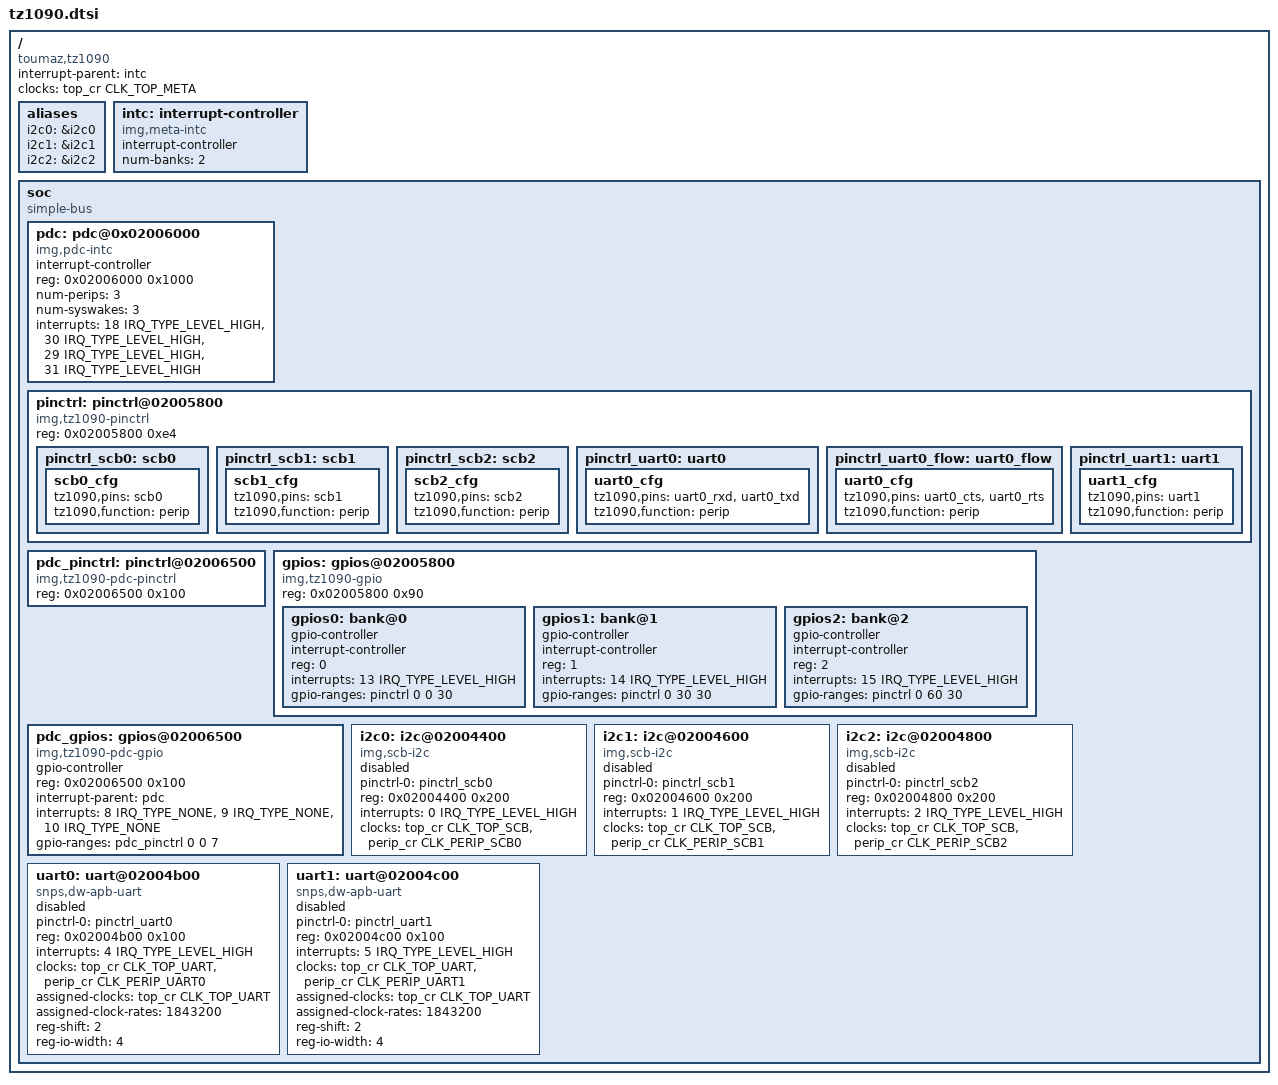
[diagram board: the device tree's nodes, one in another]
/*
 * Copyright (C) 2012 Imagination Technologies Ltd.
 *
 * This program is free software; you can redistribute it and/or modify
 * it under the terms of the GNU General Public License version 2 as
 * published by the Free Software Foundation.
 */

#include "skeleton.dtsi"

#include <dt-bindings/interrupt-controller/irq.h>
#include "tz1090_clk.dtsi"

/ {
	compatible = "toumaz,tz1090", "img,meta";

	interrupt-parent = <&intc>;

	clocks = <&top_cr CLK_TOP_META>;
	clock-names = "core";

	aliases {
		i2c0 = &i2c0;
		i2c1 = &i2c1;
		i2c2 = &i2c2;
	};

	intc: interrupt-controller {
		compatible = "img,meta-intc";
		interrupt-controller;
		#interrupt-cells = <2>;
		num-banks = <2>;
	};

	soc {
		compatible = "simple-bus";
		#address-cells = <1>;
		#size-cells = <1>;
		ranges;

		pdc: pdc@0x02006000 {
			interrupt-controller;
			#interrupt-cells = <2>;

			reg = <0x02006000 0x1000>;
			compatible = "img,pdc-intc";

			num-perips = <3>;
			num-syswakes = <3>;

			interrupts = <18 IRQ_TYPE_LEVEL_HIGH>, /* Syswakes */
			             <30 IRQ_TYPE_LEVEL_HIGH>, /* Perip 0 (RTC) */
			             <29 IRQ_TYPE_LEVEL_HIGH>, /* Perip 1 (IR) */
			             <31 IRQ_TYPE_LEVEL_HIGH>; /* Perip 2 (WDT) */
		};

		pinctrl: pinctrl@02005800 {
			#gpio-range-cells = <3>;
			compatible = "img,tz1090-pinctrl";
			reg = <0x02005800 0xe4>;

			/* common pin configurations */
			pinctrl_scb0: scb0 {
				scb0_cfg {
					tz1090,pins =	"scb0";
					tz1090,function = "perip";
				};
			};
			pinctrl_scb1: scb1 {
				scb1_cfg {
					tz1090,pins =	"scb1";
					tz1090,function = "perip";
				};
			};
			pinctrl_scb2: scb2 {
				scb2_cfg {
					tz1090,pins =	"scb2";
					tz1090,function = "perip";
				};
			};
			pinctrl_uart0: uart0 {
				uart0_cfg {
					tz1090,pins =	"uart0_rxd",
							"uart0_txd";
					tz1090,function = "perip";
				};
			};
			pinctrl_uart0_flow: uart0_flow {
				uart0_cfg {
					tz1090,pins =	"uart0_cts",
							"uart0_rts";
					tz1090,function = "perip";
				};
			};
			pinctrl_uart1: uart1 {
				uart1_cfg {
					tz1090,pins =	"uart1";
					tz1090,function = "perip";
				};
			};
		};

		pdc_pinctrl: pinctrl@02006500 {
			#gpio-range-cells = <3>;
			compatible = "img,tz1090-pdc-pinctrl";
			reg = <0x02006500 0x100>;
		};

		gpios: gpios@02005800 {
			#address-cells = <1>;
			#size-cells = <0>;
			compatible = "img,tz1090-gpio";
			reg = <0x02005800 0x90>;

			gpios0: bank@0 {
				gpio-controller;
				interrupt-controller;
				#gpio-cells = <2>;
				#interrupt-cells = <2>;
				reg = <0>;
				interrupts = <13 IRQ_TYPE_LEVEL_HIGH>;
				gpio-ranges = <&pinctrl 0 0 30>;
			};
			gpios1: bank@1 {
				gpio-controller;
				interrupt-controller;
				#gpio-cells = <2>;
				#interrupt-cells = <2>;
				reg = <1>;
				interrupts = <14 IRQ_TYPE_LEVEL_HIGH>;
				gpio-ranges = <&pinctrl 0 30 30>;
			};
			gpios2: bank@2 {
				gpio-controller;
				interrupt-controller;
				#gpio-cells = <2>;
				#interrupt-cells = <2>;
				reg = <2>;
				interrupts = <15 IRQ_TYPE_LEVEL_HIGH>;
				gpio-ranges = <&pinctrl 0 60 30>;
			};
		};

		pdc_gpios: gpios@02006500 {
			gpio-controller;
			#gpio-cells = <2>;

			compatible = "img,tz1090-pdc-gpio";
			reg = <0x02006500 0x100>;

			interrupt-parent = <&pdc>;
			interrupts =	<8  IRQ_TYPE_NONE>,
					<9  IRQ_TYPE_NONE>,
					<10 IRQ_TYPE_NONE>;
			gpio-ranges = <&pdc_pinctrl 0 0 7>;
		};

		i2c0: i2c@02004400 {
			compatible = "img,scb-i2c";
			pinctrl-names = "default";
			pinctrl-0 = <&pinctrl_scb0>;
			reg = <0x02004400 0x200>;
			interrupts = <0 IRQ_TYPE_LEVEL_HIGH>;
			clocks = <&top_cr CLK_TOP_SCB>,
				 <&perip_cr CLK_PERIP_SCB0>;
			clock-names = "scb", "sys";
			status = "disabled";
		};

		i2c1: i2c@02004600 {
			compatible = "img,scb-i2c";
			pinctrl-names = "default";
			pinctrl-0 = <&pinctrl_scb1>;
			reg = <0x02004600 0x200>;
			interrupts = <1 IRQ_TYPE_LEVEL_HIGH>;
			clocks = <&top_cr CLK_TOP_SCB>,
				 <&perip_cr CLK_PERIP_SCB1>;
			clock-names = "scb", "sys";
			status = "disabled";
		};

		i2c2: i2c@02004800 {
			compatible = "img,scb-i2c";
			pinctrl-names = "default";
			pinctrl-0 = <&pinctrl_scb2>;
			reg = <0x02004800 0x200>;
			interrupts = <2 IRQ_TYPE_LEVEL_HIGH>;
			clocks = <&top_cr CLK_TOP_SCB>,
				 <&perip_cr CLK_PERIP_SCB2>;
			clock-names = "scb", "sys";
			status = "disabled";
		};

		uart0: uart@02004b00 {
			compatible = "snps,dw-apb-uart";
			pinctrl-names = "default";
			pinctrl-0 = <	&pinctrl_uart0>;
			reg = <0x02004b00 0x100>;
			interrupts = <4 IRQ_TYPE_LEVEL_HIGH>;
			clocks = <&top_cr CLK_TOP_UART>,
				 <&perip_cr CLK_PERIP_UART0>;
			clock-names = "baudclk", "apb_pclk";
			assigned-clocks = <&top_cr CLK_TOP_UART>;
			assigned-clock-rates = <1843200>;
			reg-shift = <2>;
			reg-io-width = <4>;
			status = "disabled";
		};

		uart1: uart@02004c00 {
			compatible = "snps,dw-apb-uart";
			pinctrl-names = "default";
			pinctrl-0 = <	&pinctrl_uart1>;
			reg = <0x02004c00 0x100>;
			interrupts = <5 IRQ_TYPE_LEVEL_HIGH>;
			clocks = <&top_cr CLK_TOP_UART>,
				 <&perip_cr CLK_PERIP_UART1>;
			clock-names = "baudclk", "apb_pclk";
			assigned-clocks = <&top_cr CLK_TOP_UART>;
			assigned-clock-rates = <1843200>;
			reg-shift = <2>;
			reg-io-width = <4>;
			status = "disabled";
		};

	};
};
